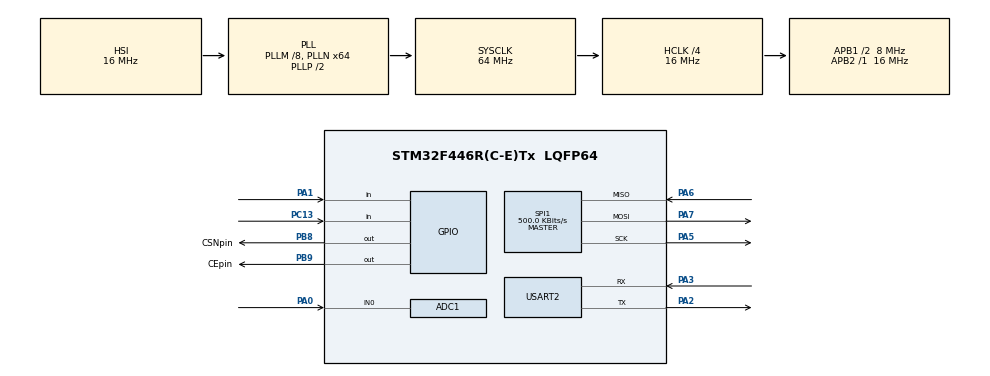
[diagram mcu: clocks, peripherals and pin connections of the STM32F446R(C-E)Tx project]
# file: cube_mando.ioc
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ADC1.Channel-0\#ChannelRegularConversion=ADC_CHANNEL_0
ADC1.ClockPrescaler=ADC_CLOCK_SYNC_PCLK_DIV8
ADC1.ContinuousConvMode=ENABLE
ADC1.NbrOfConversionFlag=1
ADC1.Rank-0\#ChannelRegularConversion=1
ADC1.Resolution=ADC_RESOLUTION_8B
ADC1.SamplingTime-0\#ChannelRegularConversion=ADC_SAMPLETIME_480CYCLES
ADC1.master=1
Mcu.Family=STM32F4
Mcu.Name=STM32F446R(C-E)Tx
Mcu.Package=LQFP64
NVIC.PriorityGroup=NVIC_PRIORITYGROUP_0
PA0-WKUP.Signal=ADCx_IN0
PA1.Signal=GPIO_Input
PA2.Mode=Asynchronous
PA2.Signal=USART2_TX
PA3.Mode=Asynchronous
PA3.Signal=USART2_RX
PA5.Mode=Full_Duplex_Master
PA5.Signal=SPI1_SCK
PA6.Mode=Full_Duplex_Master
PA6.Signal=SPI1_MISO
PA7.Mode=Full_Duplex_Master
PA7.Signal=SPI1_MOSI
PB8.GPIO_Label=CSNpin
PB8.Signal=GPIO_Output
PB9.GPIO_Label=CEpin
PB9.Signal=GPIO_Output
PC13.Signal=GPIO_Input
ProjectManager.HeapSize=0x200
ProjectManager.StackSize=0x400
ProjectManager.TargetToolchain=Makefile
RCC.48MHZClocksFreq_Value=84000000
RCC.AHBCLKDivider=RCC_SYSCLK_DIV4
RCC.AHBFreq_Value=16000000
RCC.APB1CLKDivider=RCC_HCLK_DIV2
RCC.APB1Freq_Value=8000000
RCC.APB1TimFreq_Value=16000000
RCC.APB2Freq_Value=16000000
RCC.APB2TimFreq_Value=16000000
RCC.CortexFreq_Value=16000000
RCC.FLatency-AdvancedSettings=FLASH_LATENCY_0
RCC.HCLKFreq_Value=16000000
RCC.HSE_VALUE=8000000
RCC.HSI_VALUE=16000000
RCC.PLLM=8
RCC.PLLN=64
RCC.SYSCLKFreq_VALUE=64000000
RCC.SYSCLKSource=RCC_SYSCLKSOURCE_PLLCLK
RCC.USBFreq_Value=64000000
RCC.VCOOutputFreq_Value=128000000
SH.ADCx_IN0.0=ADC1_IN0,IN0
SPI1.BaudRatePrescaler=SPI_BAUDRATEPRESCALER_32
SPI1.CalculateBaudRate=500.0 KBits/s
SPI1.Direction=SPI_DIRECTION_2LINES
SPI1.Mode=SPI_MODE_MASTER
SPI1.VirtualType=VM_MASTER
USART2.VirtualMode=VM_ASYNC
board=NUCLEO-F446RE

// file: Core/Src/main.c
/* USER CODE BEGIN Header */
/**
  ******************************************************************************
  * @file           : main.c
  * @brief          : Main program body
  ******************************************************************************
  * @attention
  *
  * Copyright (c) 2023 STMicroelectronics.
  * All rights reserved.
  *
  * This software is licensed under terms that can be found in the LICENSE file
  * in the root directory of this software component.
  * If no LICENSE file comes with this software, it is provided AS-IS.
  *
  ******************************************************************************
  */
/* USER CODE END Header */
#include "main.h"
#include "stm32f4xx_hal.h"
#include <stdio.h>
#include "MY_NRF24.h" //Hal driver del NRF
#include "fsm_adc.h"

/* USER CODE BEGIN PD */
#define TIEMPO_ADC_MS 2
/* USER CODE END PD */

ADC_HandleTypeDef hadc1;

SPI_HandleTypeDef hspi1;

UART_HandleTypeDef huart2;

void SystemClock_Config(void);
static void MX_GPIO_Init(void);
static void MX_SPI1_Init(void);
static void MX_USART2_UART_Init(void);
static void MX_ADC1_Init(void);

/* USER CODE BEGIN 0 */
uint64_t TxpipeAddrs = 0x11223344AA;
//Variables de transmisión
uint32_t myTxData[2]; //variable de envio
bool AckPayload[1]; //ACK
uint32_t adcVal;
/* USER CODE END 0 */

int main(void)

  /* Reset of all peripherals, Initializes the Flash interface and the Systick. */
  HAL_Init();

  /* Configure the system clock - Nota: el nuestro esta a 16 MHZ */
  SystemClock_Config();

  /* Initialize all configured peripherals */

  MX_GPIO_Init(); //GPIO para el botón
  MX_SPI1_Init(); //SPI para el NRFL
  MX_USART2_UART_Init();//UART para depuración
  MX_ADC1_Init();

NRF24_begin(CEpin_GPIO_Port,CSNpin_Pin,GPIO_PIN_9,hspi1);
nrf24_DebugUART_Init(huart2);

printRadioSettings(); //Resetea y printea los ajustes

// ******* SETUP DE TRANSMISIÓN CON ACK *****//
NRF24_stopListening();
NRF24_openWritingPipe(TxpipeAddrs);
NRF24_setAutoAck(true);//para enviar con ACK
NRF24_setChannel(52);//elegimos el canal
NRF24_setPayloadSize(32);//tamaño de la payload

NRF24_enableDynamicPayloads();
NRF24_enableAckPayload();

fsm_t * p_adc = fsm_adc_new(TIEMPO_ADC_MS);

  while (1)
  {
  fsm_fire(p_adc);

  HAL_Delay(10); //Periodo del bucle principal
  }
  fsm_destroy(p_adc);

}

void SystemClock_Config(void)
{
  RCC_OscInitTypeDef RCC_OscInitStruct = {0};
  RCC_ClkInitTypeDef RCC_ClkInitStruct = {0};

  /** Configure the main internal regulator output voltage
  */
  __HAL_RCC_PWR_CLK_ENABLE();
  __HAL_PWR_VOLTAGESCALING_CONFIG(PWR_REGULATOR_VOLTAGE_SCALE3);

  /** Initializes the RCC Oscillators according to the specified parameters
  * in the RCC_OscInitTypeDef structure.
  */
  RCC_OscInitStruct.OscillatorType = RCC_OSCILLATORTYPE_HSI;
  RCC_OscInitStruct.HSIState = RCC_HSI_ON;
  RCC_OscInitStruct.HSICalibrationValue = RCC_HSICALIBRATION_DEFAULT;
  RCC_OscInitStruct.PLL.PLLState = RCC_PLL_ON;
  RCC_OscInitStruct.PLL.PLLSource = RCC_PLLSOURCE_HSI;
  RCC_OscInitStruct.PLL.PLLM = 8;
  RCC_OscInitStruct.PLL.PLLN = 64;
  RCC_OscInitStruct.PLL.PLLP = RCC_PLLP_DIV2;
  RCC_OscInitStruct.PLL.PLLQ = 2;
  RCC_OscInitStruct.PLL.PLLR = 2;
  if (HAL_RCC_OscConfig(&RCC_OscInitStruct) != HAL_OK)
  {
    Error_Handler();
  }

  /** Initializes the CPU, AHB and APB buses clocks
  */
  RCC_ClkInitStruct.ClockType = RCC_CLOCKTYPE_HCLK|RCC_CLOCKTYPE_SYSCLK
                              |RCC_CLOCKTYPE_PCLK1|RCC_CLOCKTYPE_PCLK2;
  RCC_ClkInitStruct.SYSCLKSource = RCC_SYSCLKSOURCE_PLLCLK;
  RCC_ClkInitStruct.AHBCLKDivider = RCC_SYSCLK_DIV4;
  RCC_ClkInitStruct.APB1CLKDivider = RCC_HCLK_DIV2;
  RCC_ClkInitStruct.APB2CLKDivider = RCC_HCLK_DIV1;

  if (HAL_RCC_ClockConfig(&RCC_ClkInitStruct, FLASH_LATENCY_0) != HAL_OK)
  {
    Error_Handler();
  }
}

static void MX_ADC1_Init(void)
{

  ADC_ChannelConfTypeDef sConfig = {0};

  /** Configure the global features of the ADC (Clock, Resolution, Data Alignment and number of conversion)
  */
  hadc1.Instance = ADC1;
  hadc1.Init.ClockPrescaler = ADC_CLOCK_SYNC_PCLK_DIV8;
  hadc1.Init.Resolution = ADC_RESOLUTION_8B;
  hadc1.Init.ScanConvMode = DISABLE;
  hadc1.Init.ContinuousConvMode = ENABLE;
  hadc1.Init.DiscontinuousConvMode = DISABLE;
  hadc1.Init.ExternalTrigConvEdge = ADC_EXTERNALTRIGCONVEDGE_NONE;
  hadc1.Init.ExternalTrigConv = ADC_SOFTWARE_START;
  hadc1.Init.DataAlign = ADC_DATAALIGN_RIGHT;
  hadc1.Init.NbrOfConversion = 1;
  hadc1.Init.DMAContinuousRequests = DISABLE;
  hadc1.Init.EOCSelection = ADC_EOC_SINGLE_CONV;
  if (HAL_ADC_Init(&hadc1) != HAL_OK)
  {
    Error_Handler();
  }

  /** Configure for the selected ADC regular channel its corresponding rank in the sequencer and its sample time.
  */
  sConfig.Channel = ADC_CHANNEL_0;
  sConfig.Rank = 1;
  sConfig.SamplingTime = ADC_SAMPLETIME_480CYCLES;
  if (HAL_ADC_ConfigChannel(&hadc1, &sConfig) != HAL_OK)
  {
    Error_Handler();
  }

}

static void MX_SPI1_Init(void)
{

  /* SPI1 parameter configuration*/
  hspi1.Instance = SPI1;
  hspi1.Init.Mode = SPI_MODE_MASTER;
  hspi1.Init.Direction = SPI_DIRECTION_2LINES;
  hspi1.Init.DataSize = SPI_DATASIZE_8BIT;
  hspi1.Init.CLKPolarity = SPI_POLARITY_LOW;
  hspi1.Init.CLKPhase = SPI_PHASE_1EDGE;
  hspi1.Init.NSS = SPI_NSS_SOFT;
  hspi1.Init.BaudRatePrescaler = SPI_BAUDRATEPRESCALER_32;
  hspi1.Init.FirstBit = SPI_FIRSTBIT_MSB;
  hspi1.Init.TIMode = SPI_TIMODE_DISABLE;
  hspi1.Init.CRCCalculation = SPI_CRCCALCULATION_DISABLE;
  hspi1.Init.CRCPolynomial = 10;
  if (HAL_SPI_Init(&hspi1) != HAL_OK)
  {
    Error_Handler();
  }

}

static void MX_USART2_UART_Init(void)
{

  huart2.Instance = USART2;
  huart2.Init.BaudRate = 115200;
  huart2.Init.WordLength = UART_WORDLENGTH_8B;
  huart2.Init.StopBits = UART_STOPBITS_1;
  huart2.Init.Parity = UART_PARITY_NONE;
  huart2.Init.Mode = UART_MODE_TX_RX;
  huart2.Init.HwFlowCtl = UART_HWCONTROL_NONE;
  huart2.Init.OverSampling = UART_OVERSAMPLING_16;
  if (HAL_UART_Init(&huart2) != HAL_OK)
  {
    Error_Handler();
  }

}

static void MX_GPIO_Init(void)
{
  GPIO_InitTypeDef GPIO_InitStruct = {0};

  /* GPIO Ports Clock Enable */
  __HAL_RCC_GPIOC_CLK_ENABLE();
  __HAL_RCC_GPIOA_CLK_ENABLE();
  __HAL_RCC_GPIOB_CLK_ENABLE();

  /*Configure GPIO pin Output Level */
  HAL_GPIO_WritePin(GPIOB, CSNpin_Pin|CEpin_Pin, GPIO_PIN_RESET);

  /*Configure GPIO pin : PC13 */
  GPIO_InitStruct.Pin = GPIO_PIN_13;
  GPIO_InitStruct.Mode = GPIO_MODE_INPUT;
  GPIO_InitStruct.Pull = GPIO_NOPULL;
  HAL_GPIO_Init(GPIOC, &GPIO_InitStruct);

  /*Configure GPIO pin : PA1 */
  GPIO_InitStruct.Pin = GPIO_PIN_1;
  GPIO_InitStruct.Mode = GPIO_MODE_INPUT;
  GPIO_InitStruct.Pull = GPIO_NOPULL;
  HAL_GPIO_Init(GPIOA, &GPIO_InitStruct);

  /*Configure GPIO pins : CSNpin_Pin CEpin_Pin */
  GPIO_InitStruct.Pin = CSNpin_Pin|CEpin_Pin;
  GPIO_InitStruct.Mode = GPIO_MODE_OUTPUT_PP;
  GPIO_InitStruct.Pull = GPIO_NOPULL;
  GPIO_InitStruct.Speed = GPIO_SPEED_FREQ_LOW;
  HAL_GPIO_Init(GPIOB, &GPIO_InitStruct);

}

void Error_Handler(void)
{
  __disable_irq();
  while (1)
  {
  }
}
